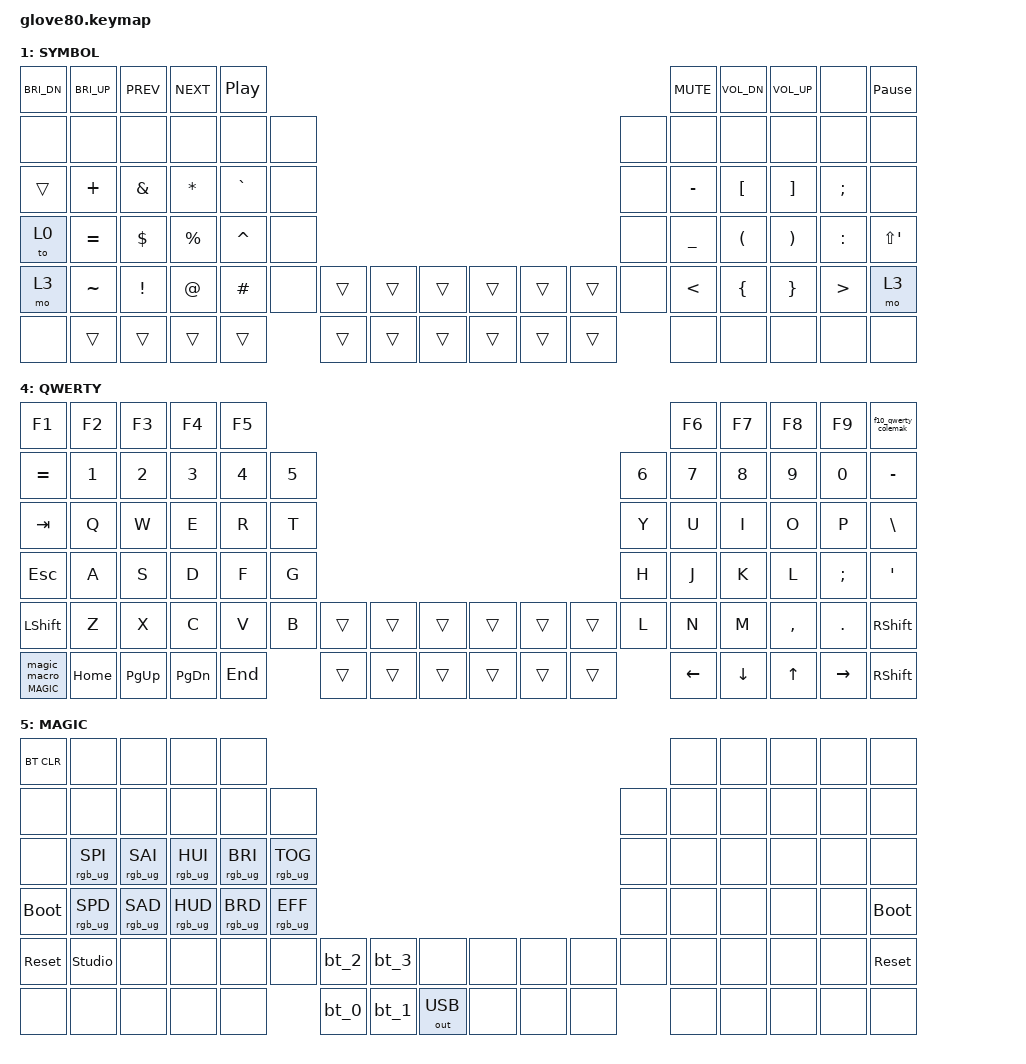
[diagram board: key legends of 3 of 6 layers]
/*
 * Copyright (c) 2020 The ZMK Contributors
 *
 * SPDX-License-Identifier: MIT
 */

#include <behaviors.dtsi>
#include <dt-bindings/zmk/bt.h>
#include <dt-bindings/zmk/keys.h>
#include <dt-bindings/zmk/outputs.h>
#include <dt-bindings/zmk/rgb.h>

#define HYPER LC(LS(LG(LALT)))
#define MEH LC(LS(LALT))

/* #define for key positions */

#define POS_LH_T1 52
#define POS_LH_T2 53
#define POS_LH_T3 54
#define POS_LH_T4 69
#define POS_LH_T5 70
#define POS_LH_T6 71
#define POS_LH_C1R2 15
#define POS_LH_C1R3 27
#define POS_LH_C1R4 39
#define POS_LH_C1R5 51
#define POS_LH_C2R1 4
#define POS_LH_C2R2 14
#define POS_LH_C2R3 26
#define POS_LH_C2R4 38
#define POS_LH_C2R5 50
#define POS_LH_C2R6 68
#define POS_LH_C3R1 3
#define POS_LH_C3R2 13
#define POS_LH_C3R3 25
#define POS_LH_C3R4 37
#define POS_LH_C3R5 49
#define POS_LH_C3R6 67
#define POS_LH_C4R1 2
#define POS_LH_C4R2 12
#define POS_LH_C4R3 24
#define POS_LH_C4R4 36
#define POS_LH_C4R5 48
#define POS_LH_C4R6 66
#define POS_LH_C5R1 1
#define POS_LH_C5R2 11
#define POS_LH_C5R3 23
#define POS_LH_C5R4 35
#define POS_LH_C5R5 47
#define POS_LH_C5R6 65
#define POS_LH_C6R1 0
#define POS_LH_C6R2 10
#define POS_LH_C6R3 22
#define POS_LH_C6R4 34
#define POS_LH_C6R5 46
#define POS_LH_C6R6 64
#define POS_RH_T1 57
#define POS_RH_T2 56
#define POS_RH_T3 55
#define POS_RH_T4 74
#define POS_RH_T5 73
#define POS_RH_T6 72
#define POS_RH_C1R2 16
#define POS_RH_C1R3 28
#define POS_RH_C1R4 40
#define POS_RH_C1R5 58
#define POS_RH_C2R1 5
#define POS_RH_C2R2 17
#define POS_RH_C2R3 29
#define POS_RH_C2R4 41
#define POS_RH_C2R5 59
#define POS_RH_C2R6 75
#define POS_RH_C3R1 6
#define POS_RH_C3R2 18
#define POS_RH_C3R3 30
#define POS_RH_C3R4 42
#define POS_RH_C3R5 60
#define POS_RH_C3R6 76
#define POS_RH_C4R1 7
#define POS_RH_C4R2 19
#define POS_RH_C4R3 31
#define POS_RH_C4R4 43
#define POS_RH_C4R5 61
#define POS_RH_C4R6 77
#define POS_RH_C5R1 8
#define POS_RH_C5R2 20
#define POS_RH_C5R3 32
#define POS_RH_C5R4 44
#define POS_RH_C5R5 62
#define POS_RH_C5R6 78
#define POS_RH_C6R1 9
#define POS_RH_C6R2 21
#define POS_RH_C6R3 33
#define POS_RH_C6R4 45
#define POS_RH_C6R5 63
#define POS_RH_C6R6 79

// layers

#define DEFAULT  0
#define SYMBOL   1
#define NUMBER   2
#define NAV      3
#define QWERTY   4
#define MAGIC    5

&caps_word { continue-list = <UNDERSCORE MINUS SPACE TAB RETURN COMMA APOS DQT GT LT EQUAL PERIOD RPAR LPAR PIPE AMPS SEMICOLON BACKSPACE DELETE LEFT_ARROW RIGHT_ARROW UP_ARROW DOWN_ARROW LSHIFT RSHIFT LCTRL RCTRL>; };

/ {
    behaviors {
        // For the "layer" key, it'd nice to be able to use it as either a shift or a toggle.
        // Configure it as a tap dance, so the first tap (or hold) is a &mo and the second tap is a &to

        lt: layer_tap {
            compatible = "zmk,behavior-hold-tap";
            #binding-cells = <2>;
            flavor = "hold-preferred";
            tapping-term-ms = <150>;
            bindings = <&mo>, <&kp>;

            display-name = "Layer-Tap";
        };

        td_esc: tap_dance_1 {
            compatible = "zmk,behavior-tap-dance";
            label = "ESC_CAPS";
            #binding-cells = <0>;
            tapping-term-ms = <200>;
            bindings = <&kp ESC>, <&kp CAPS>;
        };

        magic: magic_hold_tap {
            compatible = "zmk,behavior-hold-tap";
            label = "MAGIC_HOLD_TAP";
            #binding-cells = <2>;
            flavor = "tap-preferred";
            tapping-term-ms = <200>;
            bindings = <&mo>, <&magic_macro>;
        };

        num_sym: num_sym {
            compatible = "zmk,behavior-hold-tap";
            label = "NUM_SYM";
            bindings = <&mo>, <&to>;

            #binding-cells = <2>;
            tapping-term-ms = <200>;
        };

        f10_qwerty_colemak: f10_qwerty_colemak {
            compatible = "zmk,behavior-tap-dance";
            label = "F10_QWERTY_COLEMAK";
            #binding-cells = <0>;
            bindings = <&kp F10>, <&to 0>, <&to 4>;
        };
    };

    combos {
        compatible = "zmk,combos";

        combo_esc {
            timeout-ms = <100>;
            layers = <0>;
            key-positions = <POS_LH_C6R5 POS_RH_C6R5>;
            bindings = <&caps_word>;
        };

        c_symbols {
            bindings = <&mo 1>;
            key-positions = <46 53>;
        };
    };

    conditional_layers { compatible = "zmk,conditional-layers"; };

    macros {
        magic_macro: magic_macro_0 {
            label = "RGB_UG_STATUS";
            compatible = "zmk,behavior-macro";
            #binding-cells = <0>;
            bindings = <&rgb_ug RGB_STATUS>;
        };

        bt_0: bt_profile_macro_0 {
            label = "BT_0";
            compatible = "zmk,behavior-macro";
            #binding-cells = <0>;
            bindings = <&out OUT_BLE &bt BT_SEL 0>;
        };

        bt_1: bt_profile_macro_1 {
            label = "BT_1";
            compatible = "zmk,behavior-macro";
            #binding-cells = <0>;
            bindings = <&out OUT_BLE &bt BT_SEL 1>;
        };

        bt_2: bt_profile_macro_2 {
            label = "BT_2";
            compatible = "zmk,behavior-macro";
            #binding-cells = <0>;
            bindings = <&out OUT_BLE &bt BT_SEL 2>;
        };

        bt_3: bt_profile_macro_3 {
            label = "BT_3";
            compatible = "zmk,behavior-macro";
            #binding-cells = <0>;
            bindings = <&out OUT_BLE &bt BT_SEL 3>;
        };
    };

    keymap {
        compatible = "zmk,keymap";

        DEFAULT {
            // ---------------------------------------------------------------------------------------------------------------------------------
            // |  F1   |  F2 |  F3 |  F4  |  F5  |                                                               |  F6   |  F7   |  F8  |   F9  |  F10 |
            // |  =    |  1  |  2  |  3   |  4   |  5   |                                                 |  6   |   7   |   8   |  9   |   0   |   -  |
            // |  TAB  |  Q  |  W  |  E   |  R   |  T   |                                                 |  Y   |   U   |   I   |  O   |   P   |   \  |
            // |  ESC  |  A  |  S  |  D   |  F   |  G   |                                                 |  H   |   J   |   K   |  L   |   ;   |   '  |
            // |   `   |  Z  |  X  |  C   |  V   |  B   | LSHFT | LCTRL | SYMBOL | | LGUI  | RCTRL | RSHFT |  N   |   M   |   ,   |  .   |   /   | PGUP |
            // | MAGIC | HOME| END | LEFT | RIGHT|      | BSPC  | DEL   | LALT  | | RALT  | RET   | SPACE |      |  UP   | DOWN  |  [   |   ]   | PGDN |

            bindings = <
&kp F1          &kp F2    &kp F3       &kp F4         &kp F5                                                                                                                         &kp F6    &kp F7     &kp F8   &kp F9     &f10_qwerty_colemak
&kp EQUAL       &kp N1    &kp N2       &kp N3         &kp N4   &kp N5                                                                                                        &kp N6  &kp N7    &kp N8     &kp N9   &kp N0     &kp MINUS
&kp TAB         &kp Q     &kp W        &kp F          &kp P    &kp B                                                                                                         &kp J   &kp L     &kp U      &kp Y    &kp SEMI   &kp BSLH
&td_esc         &kp A     &kp R        &kp S          &kp T    &kp G                                                                                                         &kp M   &kp N     &kp E      &kp I    &kp O      &kp SQT
&kp LSHFT       &kp Z     &kp X        &kp C          &kp D    &kp V   &kp LCTRL  &num_sym 3 2  &kp LEFT_WIN        &kp LEFT_ALT                  &num_sym 3 2    &kp RCTRL  &kp K   &kp H     &kp COMMA  &kp DOT  &kp FSLH   &kp RSHFT
&magic MAGIC 0  &kp HOME  &kp PAGE_UP  &kp PAGE_DOWN  &kp END          &kp BSPC   &kp DELETE    &kp LS(LC(LALT))    &kp LS(LC(LA(LG(LEFT_GUI))))  &lt SYMBOL RET  &kp SPACE          &kp LEFT  &kp DOWN   &kp UP   &kp RIGHT  &kp RSHFT
            >;

            label = "BASE";
        };

        SYMBOL {
            bindings = <
&kp C_BRI_DN  &kp C_BRI_UP  &kp C_PREV  &kp C_NEXT  &kp C_PP                                                                   &kp C_MUTE     &kp C_VOL_DN  &kp C_VOL_UP  &none             &kp PAUSE_BREAK
&none         &none         &none       &none       &none      &none                                                    &none  &none          &none         &none         &none             &none
&trans        &kp PLUS      &kp AMPS    &kp STAR    &kp GRAVE  &none                                                    &none  &kp MINUS      &kp LBKT      &kp RBKT      &kp SEMI          &none
&to 0         &kp EQUAL     &kp DLLR    &kp PRCNT   &kp CARET  &none                                                    &none  &kp UNDER      &kp LPAR      &kp RPAR      &kp COLON         &kp LS(APOS)
&mo 3         &kp TILDE     &kp EXCL    &kp AT      &kp HASH   &none  &trans  &trans  &trans    &trans  &trans  &trans  &none  &kp LESS_THAN  &kp LBRC      &kp RBRC      &kp GREATER_THAN  &mo 3
&none         &trans        &trans      &trans      &trans            &trans  &trans  &trans    &trans  &trans  &trans         &none          &none         &none         &none             &none
            >;

            label = "SYMBOL";
        };

        NUMBER {
            bindings = <
&kp C_BRI_DN  &kp C_BRI_UP  &kp C_PREV  &kp C_NEXT  &kp C_PP                                                                   &kp C_MUTE    &kp C_VOL_DN  &kp C_VOL_UP  &none   &kp PAUSE_BREAK
&none         &none         &none       &none       &none     &none                                                    &none   &none         &none         &none         &none   &none
&trans        &none         &kp F7      &kp F8      &kp F9    &none                                                    &none   &kp N7        &kp N8        &kp N9        &none   &none
&to 0         &none         &kp F4      &kp F5      &kp F6    &none                                                    &none   &kp N4        &kp N5        &kp N6        &none   &none
&mo 3         &none         &kp F1      &kp F2      &kp F3    &none  &trans  &trans  &trans    &trans  &to 0   &trans  &kp N0  &kp NUMBER_1  &kp NUMBER_2  &kp NUMBER_3  &kp N0  &mo 3
&none         &trans        &trans      &trans      &trans           &trans  &trans  &trans    &trans  &trans  &kp N0          &trans        &trans        &trans        &trans
            >;

            label = "NUMBER";
        };

        NAV {
            bindings = <
&none                  &none                 &none                    &none                      &none                                                                                          &none        &none        &none        &none        &none
&kp LS(LA(LC(EQUAL)))  &none                 &none                    &none                      &none                  &none                                                      &none        &none        &none        &none        &none        &none
&kp LS(LA(LC(TAB)))    &kp LS(LC(LA(LEFT)))  &kp LS(LC(LA(DOWN)))     &kp LS(LC(LA(UP)))         &kp LS(LC(LA(RIGHT)))  &kp F23                                                    &kp LS(F18)  &kp LS(F19)  &kp LS(F20)  &kp LS(F21)  &kp LS(F22)  &none
&to 0                  &kp F13               &kp F14                  &kp F15                    &kp F16                &kp F17                                                    &kp F13      &kp F14      &kp F15      &kp F16      &kp F17      &none
&kp F24                &kp F18               &kp F19                  &kp F20                    &kp F21                &kp F22  &trans  &trans  &trans    &trans  &trans  &trans  &kp F18      &kp F19      &kp F20      &kp F21      &kp F22      &kp RIGHT_SHIFT
&none                  &kp LS(LC(LA(HOME)))  &kp LS(LC(LA(PAGE_UP)))  &kp LS(LC(LA(PAGE_DOWN)))  &kp LS(LC(LA(END)))             &trans  &trans  &trans    &trans  &trans  &trans               &kp LEFT     &kp DOWN     &kp UP       &kp RIGHT    &none
            >;

            label = "NAV";
        };

        QWERTY {
            bindings = <
&kp F1          &kp F2    &kp F3     &kp F4     &kp F5                                                                     &kp F6    &kp F7    &kp F8     &kp F9     &f10_qwerty_colemak
&kp EQUAL       &kp N1    &kp N2     &kp N3     &kp N4   &kp N5                                                    &kp N6  &kp N7    &kp N8    &kp N9     &kp N0     &kp MINUS
&kp TAB         &kp Q     &kp W      &kp E      &kp R    &kp T                                                     &kp Y   &kp U     &kp I     &kp O      &kp P      &kp BSLH
&kp ESC         &kp A     &kp S      &kp D      &kp F    &kp G                                                     &kp H   &kp J     &kp K     &kp L      &kp SEMI   &kp SQT
&kp LSHFT       &kp Z     &kp X      &kp C      &kp V    &kp B   &trans  &trans  &trans    &trans  &trans  &trans  &kp L   &kp N     &kp M     &kp COMMA  &kp DOT    &kp RSHFT
&magic MAGIC 0  &kp HOME  &kp PG_UP  &kp PG_DN  &kp END          &trans  &trans  &trans    &trans  &trans  &trans          &kp LEFT  &kp DOWN  &kp UP     &kp RIGHT  &kp RSHFT
            >;
        };

        MAGIC {
            bindings = <
&bt BT_CLR   &none            &none            &none            &none                                                                                       &none  &none  &none  &none  &none
&none        &none            &none            &none            &none            &none                                                               &none  &none  &none  &none  &none  &none
&none        &rgb_ug RGB_SPI  &rgb_ug RGB_SAI  &rgb_ug RGB_HUI  &rgb_ug RGB_BRI  &rgb_ug RGB_TOG                                                     &none  &none  &none  &none  &none  &none
&bootloader  &rgb_ug RGB_SPD  &rgb_ug RGB_SAD  &rgb_ug RGB_HUD  &rgb_ug RGB_BRD  &rgb_ug RGB_EFF                                                     &none  &none  &none  &none  &none  &bootloader
&sys_reset   &studio_unlock   &none            &none            &none            &none            &bt_2  &bt_3  &none           &none  &none  &none  &none  &none  &none  &none  &none  &sys_reset
&none        &none            &none            &none            &none                             &bt_0  &bt_1  &out OUT_USB    &none  &none  &none         &none  &none  &none  &none  &none
            >;

            label = "MAGIC";
        };
    };
};
